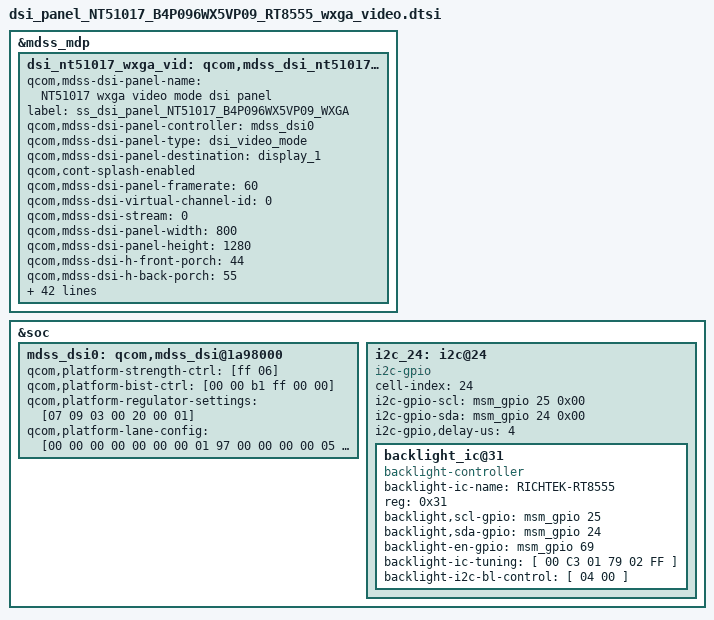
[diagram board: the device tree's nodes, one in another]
/* Copyright (c) 2013, The Linux Foundation. All rights reserved.
 *
 * This program is free software; you can redistribute it and/or modify
 * it under the terms of the GNU General Public License version 2 and
 * only version 2 as published by the Free Software Foundation.
 *
 * This program is distributed in the hope that it will be useful,
 * but WITHOUT ANY WARRANTY; without even the implied warranty of
 * MERCHANTABILITY or FITNESS FOR A PARTICULAR PURPOSE.  See the
 * GNU General Public License for more details.
 */

/*---------------------------------------------------------------------------
 * This file is autogenerated file using gcdb parser. Please do not edit it.
 * Update input XML file to add a new entry or update variable in this file
 * VERSION = "1.0"
 *---------------------------------------------------------------------------*/
&mdss_mdp {
	dsi_nt51017_wxga_vid: qcom,mdss_dsi_nt51017_wxga_video {
		qcom,mdss-dsi-panel-name = "NT51017 wxga video mode dsi panel";
		label = "ss_dsi_panel_NT51017_B4P096WX5VP09_WXGA";
		qcom,mdss-dsi-panel-controller = <&mdss_dsi0>;
		qcom,mdss-dsi-panel-type = "dsi_video_mode";
		qcom,mdss-dsi-panel-destination = "display_1";
		qcom,cont-splash-enabled;
		qcom,mdss-dsi-panel-framerate = <60>;
		qcom,mdss-dsi-virtual-channel-id = <0>;
		qcom,mdss-dsi-stream = <0>;
		qcom,mdss-dsi-panel-width = <800>;
		qcom,mdss-dsi-panel-height = <1280>;
		qcom,mdss-dsi-h-front-porch = <44>;
		qcom,mdss-dsi-h-back-porch = <55>;
		qcom,mdss-dsi-h-pulse-width = <11>;
		qcom,mdss-dsi-h-sync-skew = <0>;
		qcom,mdss-dsi-v-back-porch = <15>;
		qcom,mdss-dsi-v-front-porch = <14>;
		qcom,mdss-dsi-v-pulse-width = <1>;
		qcom,mdss-dsi-h-left-border = <0>;
		qcom,mdss-dsi-h-right-border = <0>;
		qcom,mdss-dsi-v-top-border = <0>;
		qcom,mdss-dsi-v-bottom-border = <0>;
		qcom,mdss-dsi-bpp = <24>;
		qcom,mdss-dsi-underflow-color = <0xff>;
		qcom,mdss-dsi-border-color = <0>;
		qcom,mdss-dsi-on-command-state = "dsi_hs_mode";
		qcom,mdss-dsi-off-command-state = "dsi_hs_mode";
		qcom,mdss-dsi-h-sync-pulse = <0>;
		qcom,mdss-dsi-bllp-eof-power-mode;
		qcom,mdss-dsi-bllp-power-mode;
		qcom,mdss-dsi-lane-0-state;
		qcom,mdss-dsi-lane-1-state;
		qcom,mdss-dsi-lane-2-state;
		qcom,mdss-dsi-lane-3-state;
		qcom,mdss-dsi-panel-timings = [93 1f 17 00 2f 2e 1c 21 26 03 04 00];
		qcom,mdss-dsi-t-clk-post = <0x20>;
		qcom,mdss-dsi-t-clk-pre = <0x2D>;
		qcom,mdss-dsi-bl-min-level = <1>;
		qcom,mdss-dsi-bl-max-level = <255>;
		qcom,mdss-dsi-dma-trigger = "trigger_sw";
		qcom,mdss-dsi-mdp-trigger = "none";
		qcom,mdss-dsi-bl-pmic-control-type = "bl_ctrl_ss_pwm";
		samsung,cabc_on_tx_cmds_revA = [
			39 01 00 00 00 00 02 96 3F
		];
		samsung,cabc_off_tx_cmds_revA = [
			39 01 00 00 00 00 02 96 FF
		];
		/*
		* ************************************************************************************************************************
		* Scaled level to index mappings
		* ************************************************************************************************************************
		*/
		samsung,scaled_level_map_table_revA = <
		/*<idx>	  <from>  <till> <scaled_level> */
			0		0		0		0
			1		1		10		2 /* min */
			2		11		12		3 
			3		13		14		4
			4		15		17		6
			5		18		19		8
			6		20		22		10
			7		23		24		12
			8		25		27		14
			9		28		29		16
			10		30		32		18
			11		33		34		19
			12		35		37		20
			13		38		39		21
			14		40		42		23
			15		43		44		24
			16		45		47		25
			17		48		49		26
			18		50		52		27
			19		53		54		28
			20		55		57		30
			21		58		59		32
			22		60		62		34
			23		63		64		36
			24		65		67		38
			25		68		70		40
			26		71		72		42
			27		73		75		44
			28		76		77		46
			29		78		80		48
			30		81		82		50
			31		83		85		52
			32		86		87		54
			33		88		90		56
			34		91		92		58
			35		93		95		60
			36		96		97		61
			37		98		100		62
			38		101		102		63
			39		103		105		65
			40		106		107		67
			41		108		110		69
			42		111		112		71
			43		113		115		73
			44		116		117		75
			45		118		120		77
			46		121		122		79
			47		123		125		81
			48		126		127		83
			49		128		130		85
			50		131		133		87
			51		134		135		89
			52		136		138		91
			53		139		140		93
			54		141		143		95  /* default */
			55		144		145		97
			56		146		148		99
			57		149		150		101
			58		151		153		103
			59		154		155		105
			60		156		158		107
			61		159		160		109
			62		161		163		111
			63		164		165		113
			64		166		168		115
			65		169		170		117
			66		171		173		119
			67		174		175		121
			68		176		178		123
			69		179		180		125
			70		181		183		127
			71		184		185		129
			72		186		188		131
			72		189		190		133
			74		191		193		135
			75		194		196		140
			76		197		198		144
			77		199		201		148
			78		202		203		152
			79		204		206		156
			80		207		208		160
			81		209		211		163
			82		212		213		167
			83		214		216		170
			84		217		218		173
			85		219		221		176
			86		222		223		180
			87		224		226		184
			88		227		228		187
			89		229		231		190
			90		232		233		192
			91		234		236		196
			92		237		238		200
			93		239		241		202
			94		242		243		204
			95		244		246		206
			96		247		248		208
			97		249		251		210
			98		252		253		213
			99		254		255		215 /* max */
		>;
		samsung,tft-common-support;
		qcom,mdss-dsi-init-delay-us = <30000>;
		qcom,mdss-pan-physical-width-dimension = <129>;
		qcom,mdss-pan-physical-height-dimension = <206>;
		qcom,mdss-dsi-force-clk-lane-hs;
	};
};

&soc {
	mdss_dsi0: qcom,mdss_dsi@1a98000 {
		qcom,platform-strength-ctrl = [ff 06];
		qcom,platform-bist-ctrl = [00 00 b1 ff 00 00];
		qcom,platform-regulator-settings = [07 09 03 00 20 00 01];
		qcom,platform-lane-config = [00 00 00 00 00 00 00 01 97
			00 00 00 00 05 00 00 01 97
			00 00 00 00 0a 00 00 01 97
			00 00 00 00 0f 00 00 01 97
			00 c0 00 00 00 00 00 01 bb];
		};
	
	i2c_24: i2c@24 {

		cell-index = <24>;
		compatible = "i2c-gpio";
		i2c-gpio-scl = <&msm_gpio 25  0x00>; /*scl gpio*/
		i2c-gpio-sda = <&msm_gpio 24 0x00>;  /*sda gpio*/
		i2c-gpio,delay-us = <4>;
		backlight_ic@31 {
			compatible = "backlight-controller";
			backlight-ic-name = "RICHTEK-RT8555";
			reg = <0x31>;
			backlight,scl-gpio = <&msm_gpio 25 0x00>;
			backlight,sda-gpio = <&msm_gpio 24 0x00>;
			backlight-en-gpio = <&msm_gpio 69 0x00>;
			backlight-ic-tuning = [
					00	C3
					01	79
					02	FF
			];
			backlight-i2c-bl-control = [
					04	00
			];

		};
	};
};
